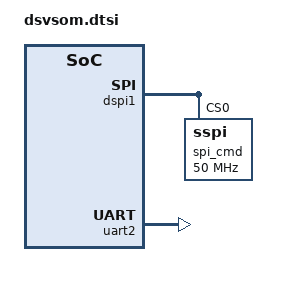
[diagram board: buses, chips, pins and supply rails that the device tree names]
/*
 * Copyright 2016 DataSoft Corp
 *
 * SPDX-License-Identifier:     GPL-2.0+ or X11
 */
#include "vf.dtsi"

/ {
	chosen {
		stdout-path = &uart2;
	};
};

&dspi1 {
	status = "okay";
	bus-num = <1>;

	spi_cmd: sspi@0 {
		reg = <0>;
		spi-max-frequency = <50000000>;
	};
};

&uart2 {
	status = "okay";
};
